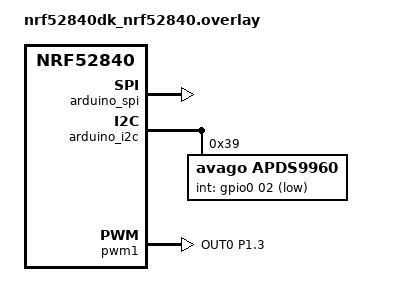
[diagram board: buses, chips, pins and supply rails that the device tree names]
/ {
   pwmleds {
      disp_bl: pwm_led_1 {
          pwms = <&pwm1 0 PWM_MSEC(1) PWM_POLARITY_NORMAL>;
      };
  };
};

disp_spi: &arduino_spi {
   status = "okay";
   cs-gpios = <&arduino_header 16 GPIO_ACTIVE_LOW>;
};

&arduino_i2c {
   status = "okay";

   apds9960: apds9960@39 {
       compatible = "avago,apds9960";
       status = "okay";
       reg = <0x39>;
       int-gpios = <&gpio0 02 (GPIO_ACTIVE_LOW | GPIO_PULL_UP)>;
   };
};

&pinctrl {
   pwm1_default: pwm1_default {
     group1 {
        psels = <NRF_PSEL(PWM_OUT0, 1, 3)>;
        nordic,invert;
     };
  };

  pwm1_sleep: pwm1_sleep {
     group1 {
        psels = <NRF_PSEL(PWM_OUT0, 1, 3)>;
        low-power-enable;
     };
  };
};

&pwm1 {
  status = "okay";
  pinctrl-0 = <&pwm1_default>;
  pinctrl-1 = <&pwm1_sleep>;
  pinctrl-names = "default", "sleep";
};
